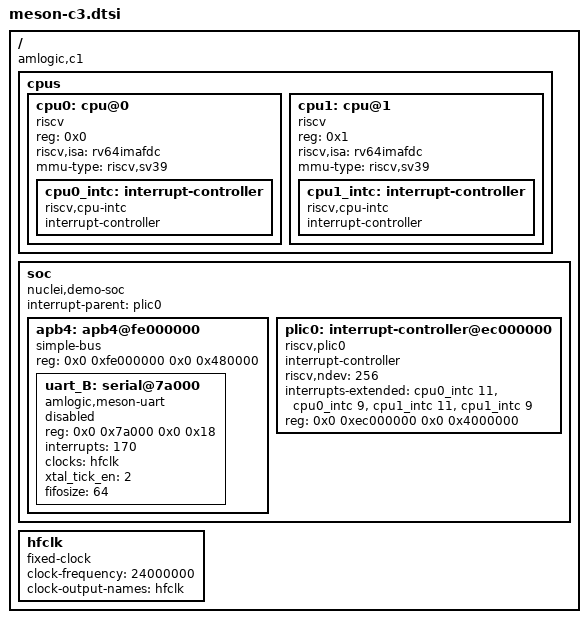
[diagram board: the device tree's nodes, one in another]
// SPDX-License-Identifier: (GPL-2.0+ OR MIT)
/*
 * Copyright (c) 2019 Amlogic, Inc. All rights reserved.
 */

#include <dt-bindings/interrupt-controller/irq.h>
#include <dt-bindings/gpio/gpio.h>

/ {
	compatible = "amlogic,c1";

	#address-cells = <2>;
	#size-cells = <2>;

	cpus {
		#address-cells = <1>;
		#size-cells = <0>;

		cpu0: cpu@0 {
			device_type = "cpu";
			reg = <0x0>;
			status = "okay";
			compatible = "riscv";
			riscv,isa = "rv64imafdc";
			mmu-type = "riscv,sv39";
			cpu0_intc: interrupt-controller {
				#interrupt-cells = <1>;
				interrupt-controller;
				compatible = "riscv,cpu-intc";
			};
		};

		cpu1: cpu@1 {
			device_type = "cpu";
			reg = <0x1>;
			status = "okay";
			compatible = "riscv";
			riscv,isa = "rv64imafdc";
			mmu-type = "riscv,sv39";
			cpu1_intc: interrupt-controller {
				#interrupt-cells = <1>;
				interrupt-controller;
				compatible = "riscv,cpu-intc";
			};
		};
	};

	soc {
		#address-cells = <2>;
		#size-cells = <2>;
		compatible = "nuclei,demo-soc", "simple-bus";
		interrupt-parent = <&plic0>;
		ranges;

		apb4: apb4@fe000000 {
			compatible = "simple-bus";
			reg = <0x0 0xfe000000 0x0 0x480000>;
			#address-cells = <2>;
			#size-cells = <2>;
			ranges = <0x0 0x0 0x0 0xfe000000 0x0 0x480000>;

			uart_B: serial@7a000 {
				compatible = "amlogic,meson-uart";
				reg = <0x0 0x7a000 0x0 0x18>;
				interrupts = <170>;
				status = "disabled";
				clocks = <&hfclk>;
				clock-names = "clk_uart";
				xtal_tick_en = <2>;
				fifosize = <64>;
				//pinctrl-names = "default";
				/*pinctrl-0 = <&ao_uart_pins>;*/
			};
		};

		plic0: interrupt-controller@ec000000 {
			#interrupt-cells = <1>;
			compatible = "riscv,plic0";
			interrupt-controller;
			riscv,ndev = <256>;
			interrupts-extended =
				<&cpu0_intc 11 &cpu0_intc 9
				&cpu1_intc 11 &cpu1_intc 9>;
			reg = <0x0 0xec000000 0x0 0x4000000>;
		};
	};

	hfclk: hfclk {
		#clock-cells = <0>;
		compatible = "fixed-clock";
		clock-frequency = <24000000>;
		clock-output-names = "hfclk";
	};

};
